# PIC32CM1216LS00048 device description
Architecture: CORTEX-M23; Family: PIC32CM; Series: PIC32CMLS00
Registers are 32-bit, read-write, reset 0x0 unless marked. A register's access mark holds for its fields unless they carry their own. Offsets are from the block's base; [hi:lo] are bit positions; lines under a group give offsets from that group; {n}, {i} and the like mark numbered series; 'fields as' and 'values as' point back to an identical list.

## PORT — Port Module
Instances: PORT 0x40003000, PORT_SEC 0x40003200, PORT_IOBUS 0x60000000, PORT_IOBUS_SEC 0x60000200
{0x0+0x80*i} GROUP[{i}] (i=0..1) group
  0x00 DIR — Data Direction
    [31:0] DIR — Port Data Direction
  0x04 DIRCLR (atomic clear of DIR) — Data Direction Clear
    [31:0] DIRCLR — Port Data Direction Clear
  0x08 DIRSET (atomic set of DIR) — Data Direction Set
    [31:0] DIRSET — Port Data Direction Set
  0x0C DIRTGL (atomic toggle of DIR) — Data Direction Toggle
    [31:0] DIRTGL — Port Data Direction Toggle
  0x10 OUT — Data Output Value
    [31:0] OUT — PORT Data Output Value
  0x14 OUTCLR (atomic clear of OUT) — Data Output Value Clear
    [31:0] OUTCLR — PORT Data Output Value Clear
  0x18 OUTSET (atomic set of OUT) — Data Output Value Set
    [31:0] OUTSET — PORT Data Output Value Set
  0x1C OUTTGL (atomic toggle of OUT) — Data Output Value Toggle
    [31:0] OUTTGL — PORT Data Output Value Toggle
  0x20 IN ro — Data Input Value
    [31:0] IN — PORT Data Input Value
  0x24 CTRL — Control
    [31:0] SAMPLING — Input Sampling Mode
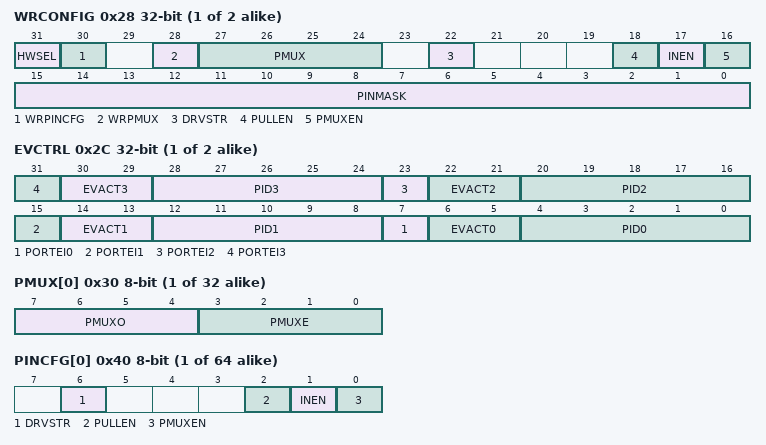
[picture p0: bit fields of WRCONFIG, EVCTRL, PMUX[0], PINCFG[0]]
  0x28 WRCONFIG wo — Write Configuration
    [31] HWSEL — Half-Word Select
    [30] WRPINCFG — Write PINCFG
    [28] WRPMUX — Write PMUX
    [27:24] PMUX — Peripheral Multiplexing
    [22] DRVSTR — Output Driver Strength Selection
    [18] PULLEN — Pull Enable
    [17] INEN — Input Enable
    [16] PMUXEN — Peripheral Multiplexer Enable
    [15:0] PINMASK — Pin Mask for Multiple Pin Configuration
  0x2C EVCTRL — Event Input Control
    [8n+7] PORTEI{n} (n=0..3) — PORT Event Input Enable {n}
    [30:29] EVACT3 — PORT Event Action 3
    [8n+4:8n] PID{n} (n=0..3) — PORT Event Pin Identifier {n}
    [22:21] EVACT2 — PORT Event Action 2
    [14:13] EVACT1 — PORT Event Action 1
    [6:5] EVACT0 — PORT Event Action 0
      0=OUT (Event output to pin); 1=SET (Set output register of pin on event); 2=CLR (Clear output register of pin on event); 3=TGL (Toggle output register of pin on event)
  {0x30+j} PMUX[{j}] (j=0..15) 8-bit — Peripheral Multiplexing
    [7:4] PMUXO — Peripheral Multiplexing for Odd-Numbered Pin
      0=A (Peripheral function A selected); 1=B (Peripheral function B selected); 2=C (Peripheral function C selected); 3=D (Peripheral function D selected); 4=E (Peripheral function E selected); 6=G (Peripheral function G selected); 7=H (Peripheral function H selected); 8=I (Peripheral function I selected); 9=J (Peripheral function J selected); 10=K (Peripheral function K selected)
    [3:0] PMUXE — Peripheral Multiplexing for Even-Numbered Pin
      values as PMUXO
  {0x40+j} PINCFG[{j}] (j=0..31) 8-bit — Pin Configuration
    [6] DRVSTR — Output Driver Strength Selection
    [2] PULLEN — Pull Enable
    [1] INEN — Input Enable
    [0] PMUXEN — Peripheral Multiplexer Enable
  0x60 INTENCLR (atomic clear) — Interrupt Enable Clear
    [0] NSCHK — Non-Secure Check Interrupt Enable
  0x64 INTENSET (atomic set) — Interrupt Enable Set
    [0] NSCHK — Non-Secure Check Interrupt Enable
  0x68 INTFLAG (atomic clear) — Interrupt Flag Status and Clear
    [0] NSCHK — Non-Secure Check
  0x6C NONSEC — Security Attribution
    [31:0] NONSEC — Port Security Attribution
  0x70 NSCHK — Security Attribution Check
    [31:0] NSCHK — Port Security Attribution Check

## RSTC — Reset Controller
Instances: RSTC 0x40000C00
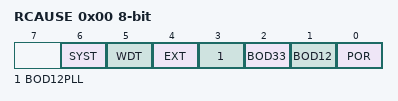
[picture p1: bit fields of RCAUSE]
0x00 RCAUSE 8-bit ro reset not defined — Reset Cause
  [6] SYST — System Reset Request
  [5] WDT — Watchdog Reset
  [4] EXT — External Reset
  [3] BOD12PLL — Brown Out VDDPLL Detector Reset
  [2] BOD33 — Brown Out VDD/AVDD Detector Reset
  [1] BOD12 — Brown Out VDDCORE Detector Reset
  [0] POR — Power On Reset

## SUPC — Supply Controller
Instances: SUPC 0x40001800
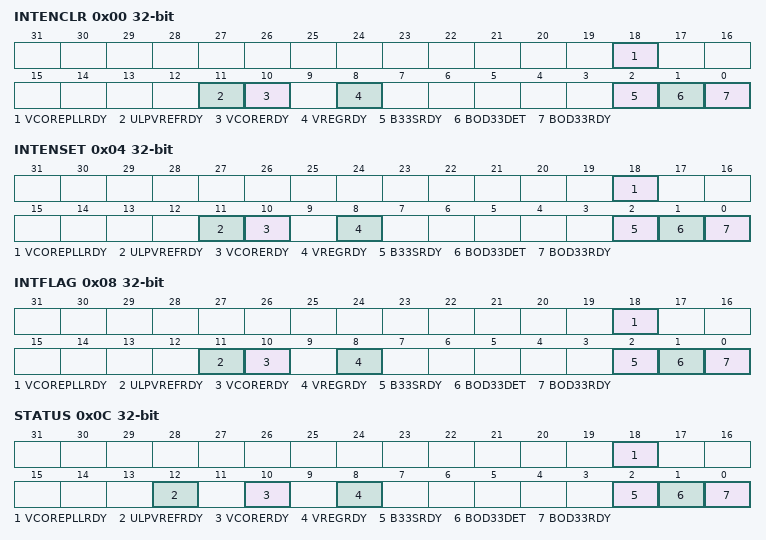
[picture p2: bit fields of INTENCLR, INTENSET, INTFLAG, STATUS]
0x00 INTENCLR (atomic clear) — Interrupt Enable Clear
  [18] VCOREPLLRDY — Voltage Regulator PLL Ready
  [11] ULPVREFRDY — ULPVREF Voltage Reference Ready
  [10] VCORERDY — VDDCORE Ready
  [8] VREGRDY — Voltage Regulator Ready
  [2] B33SRDY — BOD33 Synchronization Ready
  [1] BOD33DET — BOD33 Detection
  [0] BOD33RDY — BOD33 Ready
0x04 INTENSET (atomic set) — Interrupt Enable Set
  fields as INTENCLR
0x08 INTFLAG (atomic clear) — Interrupt Flag Status and Clear
  fields as INTENCLR
0x0C STATUS ro — Power and Clocks Status
  [18] VCOREPLLRDY — Voltage Regulator PLL Ready
  [12] ULPVREFRDY — Low Power Voltage Reference Ready
  [10] VCORERDY — VDDCORE Ready
  [8] VREGRDY — Voltage Regulator Ready
  [2] B33SRDY — BOD33 Synchronization Ready
  [1] BOD33DET — BOD33 Detection
  [0] BOD33RDY — BOD33 Ready
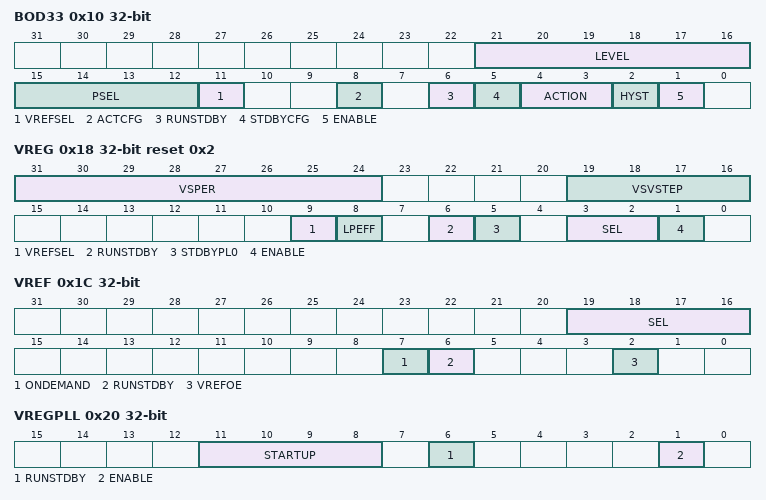
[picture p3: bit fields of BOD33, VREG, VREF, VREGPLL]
0x10 BOD33 (WSYNC) — BOD33 Control
  [21:16] LEVEL — Threshold Level for VDD/AVDD
  [15:12] PSEL — Prescaler Select
    0=DIV2 (Divide clock by 2); 1=DIV4 (Divide clock by 4); 2=DIV8 (Divide clock by 8); 3=DIV16 (Divide clock by 16); 4=DIV32 (Divide clock by 32); 5=DIV64 (Divide clock by 64); 6=DIV128 (Divide clock by 128); 7=DIV256 (Divide clock by 256); 8=DIV512 (Divide clock by 512); 9=DIV1024 (Divide clock by 1024); 10=DIV2048 (Divide clock by 2048); 11=DIV4096 (Divide clock by 4096); 12=DIV8192 (Divide clock by 8192); 13=DIV16384 (Divide clock by 16384); 14=DIV32768 (Divide clock by 32768); 15=DIV65536 (Divide clock by 65536)
  [11] VREFSEL — BOD33 Voltage Reference Selection
    0=SEL_VREF (Selects VREF for the BOD33); 1=SEL_ULPVREF (Selects ULPVREF for the BOD33)
  [8] ACTCFG — Configuration in Active mode
  [6] RUNSTDBY — Run during Standby
  [5] STDBYCFG — Configuration in Standby mode
  [4:3] ACTION — Action when Threshold Crossed
    0=NONE (No action); 1=RESET (The BOD33 generates a reset); 2=INT (The BOD33 generates an interrupt)
  [2] HYST — Hysteresis Enable
  [1] ENABLE
0x18 VREG reset 0x2 — VREG Control
  [31:24] VSPER — Voltage Scaling Period
  [19:16] VSVSTEP — Voltage Scaling Voltage Step
  [9] VREFSEL — Voltage Regulator Voltage Reference Selection
    0=SEL_VREF (Selects VREF for the VREG); 1=SEL_ULPVREF (Selects ULPVREF for the VREG)
  [8] LPEFF — Low Power efficiency
  [6] RUNSTDBY — Run during Standby
  [5] STDBYPL0 — Standby in PL0
  [3:2] SEL — Voltage Regulator Selection in active mode
    0=LDO (LDO selection); 1=BUCK (Buck selection)
  [1] ENABLE
0x1C VREF — VREF Control
  [19:16] SEL — Voltage Reference Selection for ADC/DAC
    6=2V4 (2.4V voltage reference typical value); 7=2V5 (2.5V voltage reference typical value)
  [7] ONDEMAND — On Demand Control
  [6] RUNSTDBY — Run during Standby
  [2] VREFOE — Voltage Reference Output Enable
0x20 VREGPLL — VREGPLL Control
  [11:8] STARTUP — Startup Time
  [6] RUNSTDBY — Run during Standby
  [1] ENABLE — Vreg PLL Enable
0x2C EVCTRL — Event Control
  [1] BOD33DETEO — BOD33 Detection Event Output Enable
